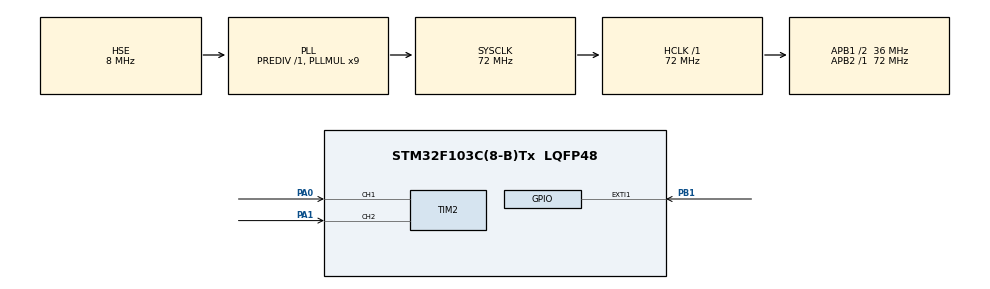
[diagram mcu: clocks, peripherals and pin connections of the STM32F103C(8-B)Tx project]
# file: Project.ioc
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Mcu.Family=STM32F1
Mcu.Name=STM32F103C(8-B)Tx
Mcu.Package=LQFP48
NVIC.PriorityGroup=NVIC_PRIORITYGROUP_4
NVIC.TIM1_UP_IRQn=true\:0\:0\:false\:false\:true\:true\:true\:true
PA0-WKUP.GPIO_PuPd=GPIO_PULLUP
PA0-WKUP.Signal=S_TIM2_CH1_ETR
PA1.GPIO_PuPd=GPIO_PULLUP
PA1.Signal=S_TIM2_CH2
PA13.Mode=Serial_Wire
PA13.Signal=SYS_JTMS-SWDIO
PA14.Mode=Serial_Wire
PA14.Signal=SYS_JTCK-SWCLK
PB1.GPIO_ModeDefaultEXTI=GPIO_MODE_IT_FALLING
PB1.GPIO_PuPd=GPIO_PULLUP
PB1.Signal=GPXTI1
PD0-OSC_IN.Mode=HSE-External-Oscillator
PD0-OSC_IN.Signal=RCC_OSC_IN
PD1-OSC_OUT.Mode=HSE-External-Oscillator
PD1-OSC_OUT.Signal=RCC_OSC_OUT
ProjectManager.HeapSize=0x200
ProjectManager.StackSize=0x400
ProjectManager.TargetToolchain=MDK-ARM V5.32
RCC.AHBFreq_Value=72000000
RCC.APB1CLKDivider=RCC_HCLK_DIV2
RCC.APB1Freq_Value=36000000
RCC.APB1TimFreq_Value=72000000
RCC.APB2Freq_Value=72000000
RCC.APB2TimFreq_Value=72000000
RCC.HCLKFreq_Value=72000000
RCC.PLLMUL=RCC_PLL_MUL9
RCC.PLLSourceVirtual=RCC_PLLSOURCE_HSE
RCC.SYSCLKFreq_VALUE=72000000
RCC.SYSCLKSource=RCC_SYSCLKSOURCE_PLLCLK
RCC.USBFreq_Value=72000000
SH.S_TIM2_CH1_ETR.0=TIM2_CH1,Encoder_Interface
SH.S_TIM2_CH2.0=TIM2_CH2,Encoder_Interface
TIM1.AutoReloadPreload=TIM_AUTORELOAD_PRELOAD_ENABLE
TIM1.Period=2499
TIM1.Prescaler=7199
TIM2.EncoderMode=TIM_ENCODERMODE_TI12
TIM2.IC1Filter=6
TIM2.IC2Filter=6
VP_TIM1_VS_ClockSourceINT.Mode=Internal
board=custom

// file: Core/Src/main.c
/* USER CODE BEGIN Header */
/**
  ******************************************************************************
  * @file           : main.c
  * @brief          : Main program body
  ******************************************************************************
  * @attention
  *
  * Copyright (c) 2026 STMicroelectronics.
  * All rights reserved.
  *
  * This software is licensed under terms that can be found in the LICENSE file
  * in the root directory of this software component.
  * If no LICENSE file comes with this software, it is provided AS-IS.
  *
  ******************************************************************************
  */
/* USER CODE END Header */
#include "main.h"
#include "tim.h"
#include "gpio.h"

/* USER CODE BEGIN Includes */
#include "OLED.h"
#include "LED.h"
#include "Key.h"
#include "Timer.h"
/* USER CODE END Includes */

void SystemClock_Config(void);

int main(void)
{

  /* MCU Configuration--------------------------------------------------------*/

  /* Reset of all peripherals, Initializes the Flash interface and the Systick. */
  HAL_Init();

  /* USER CODE BEGIN Init */
	OLED_Init();	//初始化OLED
  /* USER CODE END Init */

  /* Configure the system clock */
  SystemClock_Config();

  /* Initialize all configured peripherals */
  MX_GPIO_Init();
  MX_TIM1_Init();
  MX_TIM2_Init();
  /* USER CODE BEGIN 2 */
  	Encoder_Start(); 	//调用HAL_TIM_Encoder_Start启动编码器计数，记得一定要放到TIM初始化后面！！
	TIM1_ITStart();		//调用HAL_TIM_Base_Start_IT开启中断
  OLED_ShowString(1, 1, "CNT:");
  OLED_ShowString(2, 1, "Speed:");

  /* USER CODE END 2 */

  /* Infinite loop */
  /* USER CODE BEGIN WHILE */
  while (1)
  {
	OLED_ShowSignedNum(1, 6, Encoder_GetCNT());	//刷新CNT;
	OLED_ShowSignedNum(2, 8, Encoder_Speed);	//显示速度

    /* USER CODE END WHILE */

  }
}

void SystemClock_Config(void)
{
  RCC_OscInitTypeDef RCC_OscInitStruct = {0};
  RCC_ClkInitTypeDef RCC_ClkInitStruct = {0};

  /** Initializes the RCC Oscillators according to the specified parameters
  * in the RCC_OscInitTypeDef structure.
  */
  RCC_OscInitStruct.OscillatorType = RCC_OSCILLATORTYPE_HSE;
  RCC_OscInitStruct.HSEState = RCC_HSE_ON;
  RCC_OscInitStruct.HSEPredivValue = RCC_HSE_PREDIV_DIV1;
  RCC_OscInitStruct.HSIState = RCC_HSI_ON;
  RCC_OscInitStruct.PLL.PLLState = RCC_PLL_ON;
  RCC_OscInitStruct.PLL.PLLSource = RCC_PLLSOURCE_HSE;
  RCC_OscInitStruct.PLL.PLLMUL = RCC_PLL_MUL9;
  if (HAL_RCC_OscConfig(&RCC_OscInitStruct) != HAL_OK)
  {
    Error_Handler();
  }

  /** Initializes the CPU, AHB and APB buses clocks
  */
  RCC_ClkInitStruct.ClockType = RCC_CLOCKTYPE_HCLK|RCC_CLOCKTYPE_SYSCLK
                              |RCC_CLOCKTYPE_PCLK1|RCC_CLOCKTYPE_PCLK2;
  RCC_ClkInitStruct.SYSCLKSource = RCC_SYSCLKSOURCE_PLLCLK;
  RCC_ClkInitStruct.AHBCLKDivider = RCC_SYSCLK_DIV1;
  RCC_ClkInitStruct.APB1CLKDivider = RCC_HCLK_DIV2;
  RCC_ClkInitStruct.APB2CLKDivider = RCC_HCLK_DIV1;

  if (HAL_RCC_ClockConfig(&RCC_ClkInitStruct, FLASH_LATENCY_2) != HAL_OK)
  {
    Error_Handler();
  }
}

void Error_Handler(void)
{
  __disable_irq();
  while (1)
  {
  }
}
